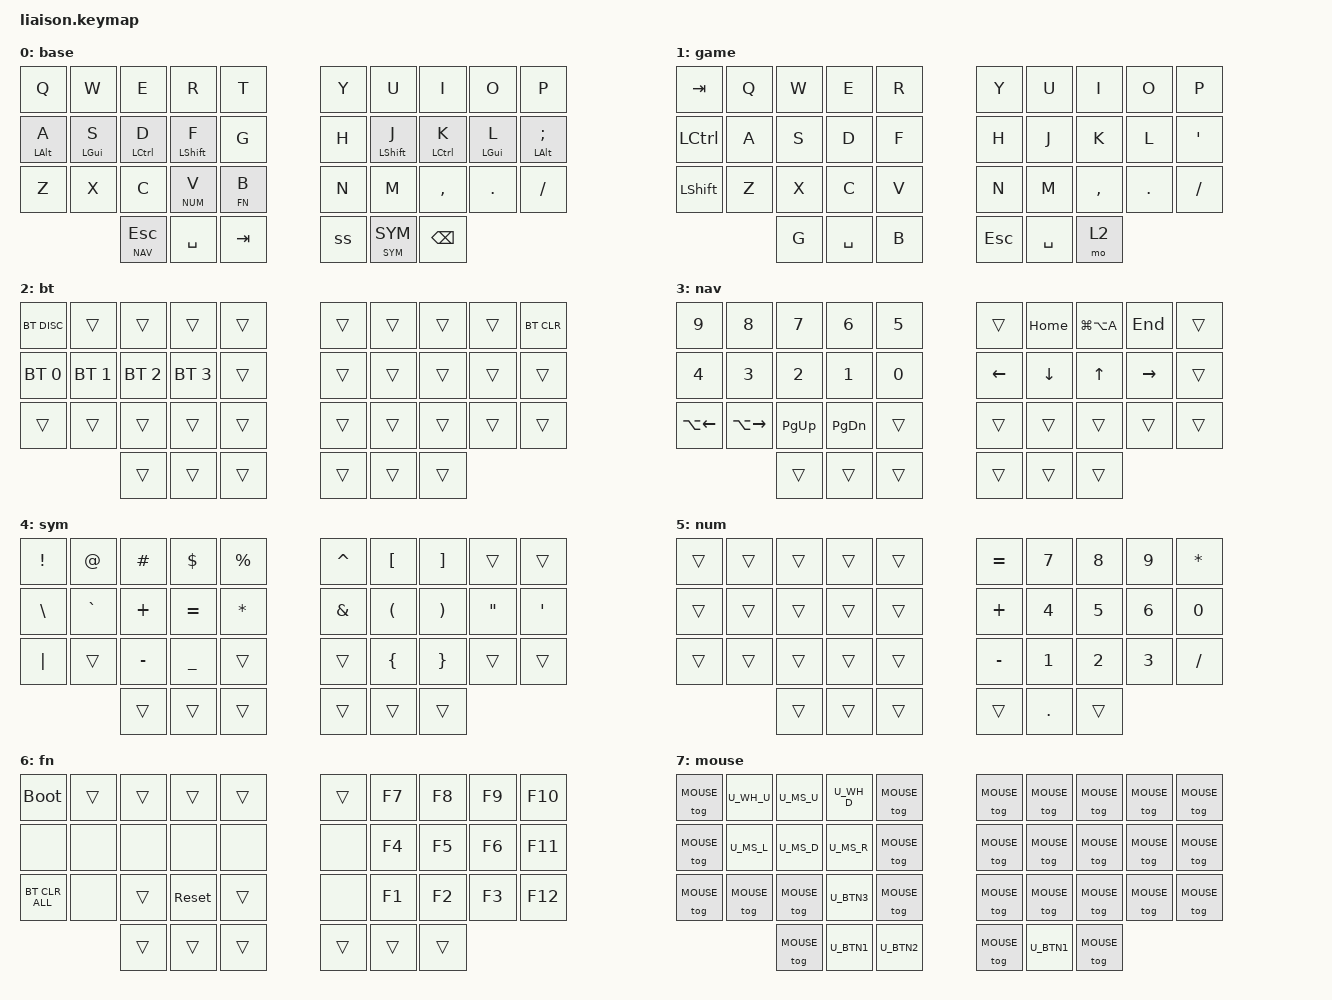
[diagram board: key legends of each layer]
#include <dt-bindings/zmk/outputs.h> // enable output switching to USB
#include <behaviors.dtsi>
#include <dt-bindings/zmk/keys.h>
#include <dt-bindings/zmk/bt.h>
#include "./mouse.dtsi"

/* Layers (Must be all caps. Layers can only access other layers that appear later in the stack, ie layer 7 cannot access layer 0. */
# define BASE   0
# define GAME   1
# define BT     2
# define NAV    3
# define SYM    4
# define NUM    5
# define FN     6
# define MOUSE  7

/* Abstractions */
// tapping-term-ms = time before hold is triggered on same side
#define HM_TAPPING_TERM 300
// quick-tap-ms = repeat on tap-into-hold occurs after this time
#define HM_TAPPING_TERM_FAST 200
// require-prior-idle-ms = if HRM was pressed n ms after a key was tapped, output a tap instead of a mod.
#define HM_PRIOR_IDLE 105

#define KEYS_L 0 1 2 3 4 10 11 12 13 14 20 21 22 23 24
#define KEYS_R 5 6 7 8 9 15 16 17 18 19 27 28 29 30 31
#define KEYS_T 25 26 32 33 34 35 36 37

#define COMBO(NAME, BINDINGS, KEYPOS, LAYERS, TIME) \
  combo_##NAME { \
    timeout-ms = <TIME>; \
    bindings = <BINDINGS>; \
    key-positions = <KEYPOS>; \
    layers = <LAYERS>; \
  };

/* Behavior settings */
&caps_word {
    continue-list = <UNDER MINUS>;
};
&sk { //sticky key
    release-after-ms = <100>;
    quick-release; // no double capitalization when rolling keys
};
&sl {
    release-after-ms = <100>;
};

/* Key positions
 0  1  2  3  4  5  6  7  8  9
10 11 12 13 14  15 16 17 18 19
20 21 22 23 24  25 26 27 28 29
     [30]31 32  33 34[35]          */

/ {
    macros {
        awm: awm {
            compatible = "zmk,behavior-macro";
            #binding-cells = <0>;
            wait-ms = <0>;
            bindings =
                <&macro_press &mo NAV &kp LGUI>,
                <&macro_pause_for_release>,
                <&macro_release &mo NAV &kp LGUI>;
            };
        };

    behaviors {
        ss: smart_shift {
            compatible = "zmk,behavior-tap-dance";
            #binding-cells = <0>;
            tapping-term-ms = <400>;
            bindings = <&sk LSHFT>, <&caps_word>;
        };
        wm: window_man {
            compatible = "zmk,behavior-hold-tap";
            #binding-cells = <2>;
            flavor = "hold-preferred";
            tapping-term-ms = <280>;
            bindings = <&awm>, <&sk>; // pass 0 as a dummy binding for the awm macro
        };
        mo_sl: mo_sl {
            compatible = "zmk,behavior-hold-tap";
            #binding-cells = <2>;
            flavor = "balanced";
            tapping-term-ms = <280>;
            bindings = <&mo>, <&sl>;
        };
        hml: homerow_mods_left {
            compatible = "zmk,behavior-hold-tap";
            #binding-cells = <2>;
            flavor = "balanced";
            tapping-term-ms = <HM_TAPPING_TERM>;
            quick-tap-ms = <175>;
            require-prior-idle-ms = <HM_PRIOR_IDLE>;
            hold-trigger-key-positions = <KEYS_R KEYS_T>;
            hold-trigger-on-release;
            bindings = <&kp>, <&kp>;
        };
        hmr: homerow_mods_right {
            compatible = "zmk,behavior-hold-tap";
            #binding-cells = <2>;
            flavor = "balanced";
            tapping-term-ms = <HM_TAPPING_TERM>;
            quick-tap-ms = <175>;
            require-prior-idle-ms = <HM_PRIOR_IDLE>;
            hold-trigger-key-positions = <KEYS_L KEYS_T>;
            hold-trigger-on-release;
            bindings = <&kp>, <&kp>;
        };
        lmk: left_mo_kp {
            compatible = "zmk,behavior-hold-tap";
            #binding-cells = <2>;
            flavor = "balanced";
            tapping-term-ms = <HM_TAPPING_TERM>;
            quick-tap-ms = <175>;
            require-prior-idle-ms = <HM_PRIOR_IDLE>;
            hold-trigger-key-positions = <KEYS_R KEYS_T>;
            hold-trigger-on-release;
            bindings = <&mo>, <&kp>;
        };
        rmk: right_mo_kp {
            compatible = "zmk,behavior-hold-tap";
            #binding-cells = <2>;
            flavor = "balanced";
            tapping-term-ms = <HM_TAPPING_TERM>;
            quick-tap-ms = <175>;
            require-prior-idle-ms = <HM_PRIOR_IDLE>;
            hold-trigger-key-positions = <KEYS_L KEYS_T>;
            hold-trigger-on-release;
            bindings = <&mo>, <&kp>;
        };
        hml_sh: homerow_shift_left {
            compatible = "zmk,behavior-hold-tap";
            #binding-cells = <2>;
            flavor = "balanced";
            tapping-term-ms = <200>;
            quick-tap-ms = <175>;
            require-prior-idle-ms = <HM_PRIOR_IDLE>;
            hold-trigger-key-positions = <KEYS_R KEYS_T>;
            hold-trigger-on-release;
            bindings = <&kp>, <&kp>;
        };
        hmr_sh: homerow_shift_right {
            compatible = "zmk,behavior-hold-tap";
            #binding-cells = <2>;
            flavor = "balanced";
            tapping-term-ms = <200>;
            quick-tap-ms = <175>;
            require-prior-idle-ms = <HM_PRIOR_IDLE>;
            hold-trigger-key-positions = <KEYS_L KEYS_T>;
            hold-trigger-on-release;
            bindings = <&kp>, <&kp>;
        }; 
    };

    combos {
        compatible = "zmk,combos";
     /* COMBO(NAME, BINDING, KEYPOS, LAYERS, TIME) */
        COMBO(ldelete, &kp DEL, 11 13, BASE, 25)
        COMBO(rdelete, &kp DEL, 17 18, BASE GAME, 25)
        COMBO(ss, &ss, 35 36, BASE, 30)
        COMBO(lenter, &kp ENTER, 12 13, BASE, 30)
        COMBO(renter, &kp ENTER, 16 17, BASE GAME, 30)
        COMBO(caps, &kp CAPS, 16 18, BASE, 25)
        COMBO(printscreen, &kp PSCRN, 8 18, BASE, 25)
        COMBO(wm, &wm 0 LGUI, 31 32, BASE, 500)
        COMBO(warpd, &kp LG(LA(A)), 7 17, BASE, 25)

        COMBO(mouse, &tog MOUSE, 11 12, BASE MOUSE, 15)
        COMBO(game, &tog GAME, 1 2 3, BASE GAME, 25)
        // COMBO(usbbt, &out OUT_TOG, 0 10, BASE)
        // COMBO(btclr, &bt BT_CLR, 1 11, BASE)
    };

    keymap {
        compatible = "zmk,keymap";

        base {
            bindings = <
    &kp Q &kp W &kp E &kp R &kp T                                             &kp Y &kp U &kp I &kp O &kp P
    &hml LALT A &hml LGUI S &hml LCTRL D &hml_sh LSHFT F &kp G                       &kp H &hmr_sh LSHFT J &hmr LCTRL K &hmr LGUI L &hmr LALT SEMI
    &kp Z &kp X &kp C &lmk NUM V &lmk FN B                                       &kp N &kp M  &kp CMMA &kp DOT &kp SLASH
                                 &lt NAV ESC &kp SPACE &kp TAB            &ss &mo_sl SYM SYM &kp BSPC
            >;
        };

        game {
            bindings = <
    &kp TAB &kp Q &kp W &kp E &kp R                                             &kp Y &kp U &kp I &kp O &kp P
    &kp LCTRL &kp A &kp S &kp D &kp F                                             &kp H &kp J &kp K &kp L &kp QUOT
    &kp LSHFT &kp Z &kp X &kp C &kp V                             &kp N &kp M  &kp CMMA &kp DOT &kp SLASH
                                 &kp G &kp SPACE &kp B            &kp ESC &kp SPC &mo 2
            >;
        };

        bt {
            bindings = <
    &bt BT_DISC &trans &trans &trans &trans                                        &trans &trans &trans &trans &bt BT_CLR
    &bt BT_SEL 0 &bt BT_SEL 1 &bt BT_SEL 2 &bt BT_SEL 3 &trans                     &trans &trans &trans &trans &trans
    &trans &trans &trans &trans &trans                            &trans &trans &trans &trans &trans
                                &trans &trans &trans            &trans &trans &trans
            >;
        };

        nav {
            bindings = <
    &kp N9 &kp N8 &kp N7 &kp N6 &kp N5                                        &trans &kp HOME &kp LG(LA(A)) &kp END &trans
    &kp N4 &kp N3 &kp N2 &kp N1 &kp N0                                        &kp LEFT &kp DOWN &kp UP &kp RIGHT &trans
    &kp LA(LEFT) &kp LA(RIGHT) &kp PG_UP &kp PG_DN &trans                             &trans &trans &trans &trans &trans
                                &trans &trans &trans            &trans &trans &trans
            >;
        };

        sym {
            bindings = <
    &kp EXCL &kp AT &kp HASH &kp DLLR &kp PRCNT                                        &kp CARET &kp LBKT &kp RBKT &trans &trans
    &kp BSLH &kp GRAVE &kp PLUS &kp EQUAL &kp STAR                                        &kp AMPS &kp LPAR &kp RPAR &kp DQT &kp SQT
    &kp PIPE &trans &kp MINUS &kp UNDER &trans                            &trans &kp LBRC &kp RBRC &trans &trans
                                &trans &trans &trans            &trans &trans &trans
            >;
        };

        num {
            bindings = <
    &trans &trans &trans &trans &trans                                        &kp EQUAL  &kp N7 &kp N8 &kp N9 &kp STAR
    &trans &trans &trans &trans &trans                                        &kp PLUS  &kp N4 &kp N5 &kp N6 &kp N0
    &trans &trans &trans &trans &trans                            &kp MINUS &kp N1 &kp N2 &kp N3 &kp SLASH
                                &trans &trans &trans            &trans &kp DOT &trans
            >;
        };

        fn {
            bindings = <
    &bootloader &trans &trans &trans &trans                                        &trans &kp F7 &kp F8 &kp F9 &kp F10
    &none &none &none &none &none                                        &none &kp F4 &kp F5 &kp F6 &kp F11
    &bt BT_CLR_ALL &none &trans &sys_reset &trans                            &none &kp F1 &kp F2 &kp F3 &kp F12 
                                &trans &trans &trans            &trans &trans &trans
            >;
        };

        mouse {
            bindings = <
    &tog MOUSE U_WH_U U_MS_U U_WH_D &tog MOUSE                                        &tog MOUSE &tog MOUSE &tog MOUSE &tog MOUSE &tog MOUSE
    &tog MOUSE U_MS_L U_MS_D U_MS_R &tog MOUSE                                        &tog MOUSE &tog MOUSE &tog MOUSE &tog MOUSE &tog MOUSE
    &tog MOUSE &tog MOUSE &tog MOUSE U_BTN3 &tog MOUSE                            &tog MOUSE &tog MOUSE &tog MOUSE &tog MOUSE &tog MOUSE
                                &tog MOUSE U_BTN1 U_BTN2            &tog MOUSE U_BTN1 &tog MOUSE >;
        };
    };
};
